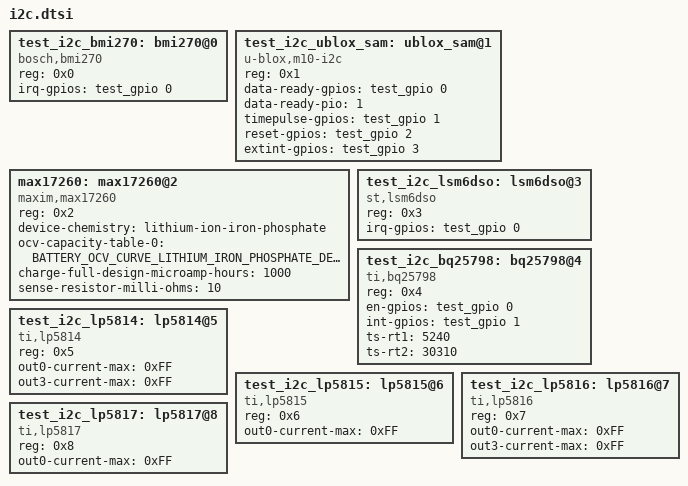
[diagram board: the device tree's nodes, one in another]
/*
 * Copyright (c) 2020, Linaro Ltd.
 *
 * SPDX-License-Identifier: Apache-2.0
 *
 * Application overlay for i2c devices
 */

#include <zephyr/dt-bindings/battery/battery.h>

/****************************************
 * PLEASE KEEP REG ADDRESSES SEQUENTIAL *
 ***************************************/

test_i2c_bmi270: bmi270@0 {
	compatible = "bosch,bmi270";
	reg = <0x0>;
	irq-gpios = <&test_gpio 0 0>;
};

test_i2c_ublox_sam: ublox_sam@1 {
	compatible = "u-blox,m10-i2c";
	reg = <0x1>;
	data-ready-gpios = <&test_gpio 0 0>;
	data-ready-pio = <1>;
	timepulse-gpios = <&test_gpio 1 0>;
	reset-gpios = <&test_gpio 2 0>;
	extint-gpios = <&test_gpio 3 0>;
};

max17260: max17260@2 {
	compatible = "maxim,max17260";
	reg = <0x2>;
	device-chemistry = "lithium-ion-iron-phosphate";
	ocv-capacity-table-0 = <BATTERY_OCV_CURVE_LITHIUM_IRON_PHOSPHATE_DEFAULT>;
	charge-full-design-microamp-hours = <1000>;
	sense-resistor-milli-ohms = <10>;
};

test_i2c_lsm6dso: lsm6dso@3 {
	compatible = "st,lsm6dso";
	reg = <0x3>;
	irq-gpios = <&test_gpio 0 0>;
};

test_i2c_bq25798: bq25798@4 {
	compatible = "ti,bq25798";
	reg = <0x4>;
	en-gpios = <&test_gpio 0 0>;
	int-gpios = <&test_gpio 1 0>;
	ts-rt1 = <5240>;
	ts-rt2 = <30310>;
};

test_i2c_lp5814: lp5814@5 {
	compatible = "ti,lp5814";
	reg = <0x5>;
	out0-current-max = <0xFF>;
	out3-current-max = <0xFF>;
};

test_i2c_lp5815: lp5815@6 {
	compatible = "ti,lp5815";
	reg = <0x6>;
	out0-current-max = <0xFF>;
};

test_i2c_lp5816: lp5816@7 {
	compatible = "ti,lp5816";
	reg = <0x7>;
	out0-current-max = <0xFF>;
	out3-current-max = <0xFF>;
};

test_i2c_lp5817: lp5817@8 {
	compatible = "ti,lp5817";
	reg = <0x8>;
	out0-current-max = <0xFF>;
};
